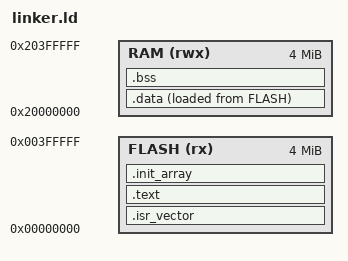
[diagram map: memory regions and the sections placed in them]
ENTRY(Reset_Handler)

MEMORY
{
    FLASH (rx)  : ORIGIN = 0x00000000, LENGTH = 4M
    RAM   (rwx) : ORIGIN = 0x20000000, LENGTH = 4M
}

_estack = ORIGIN(RAM) + LENGTH(RAM);

SECTIONS
{
    .isr_vector : {
        KEEP(*(.isr_vector))
    } > FLASH

    .text : {
        *(.text*)
        *(.rodata*)
        . = ALIGN(4);
    } > FLASH

    .init_array : {
        . = ALIGN(4);
        __init_array_start = .;
        KEEP(*(SORT(.init_array.*)))
        KEEP(*(.init_array))
        __init_array_end = .;
    } > FLASH

    _sidata = LOADADDR(.data);

    .data : {
        _sdata = .;
        *(.data*)
        . = ALIGN(4);
        _edata = .;
    } > RAM AT > FLASH

    .bss : {
        _sbss = .;
        *(.bss*)
        *(COMMON)
        . = ALIGN(4);
        _ebss = .;
    } > RAM

    . = ALIGN(8);
    end = .;          /* début du tas : requis par _sbrk de libnosys */
    _end = end;

    /DISCARD/ : {
        *(.ARM.exidx*)
        *(.ARM.extab*)
    }
}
